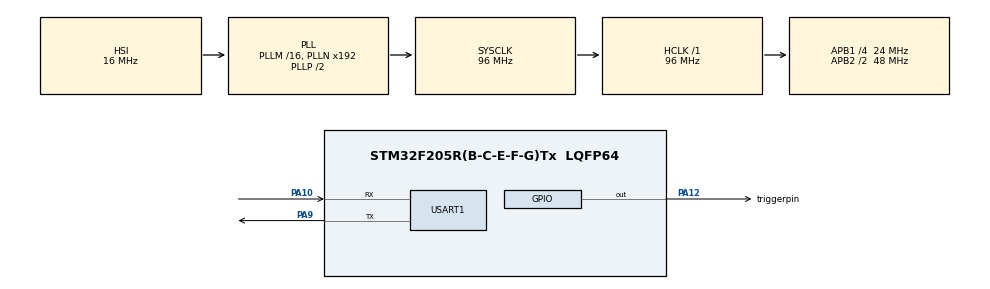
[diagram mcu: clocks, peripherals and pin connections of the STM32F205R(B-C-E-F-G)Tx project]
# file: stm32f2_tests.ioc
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Mcu.Family=STM32F2
Mcu.Name=STM32F205R(B-C-E-F-G)Tx
Mcu.Package=LQFP64
NVIC.PriorityGroup=NVIC_PRIORITYGROUP_4
PA10.Mode=Asynchronous
PA10.Signal=USART1_RX
PA12.GPIO_Label=triggerpin
PA12.GPIO_Speed=GPIO_SPEED_FREQ_VERY_HIGH
PA12.Signal=GPIO_Output
PA9.Mode=Asynchronous
PA9.Signal=USART1_TX
ProjectManager.HeapSize=0x200
ProjectManager.StackSize=0x400
ProjectManager.TargetToolchain=STM32CubeIDE
RCC.48MHZClocksFreq_Value=48000000
RCC.AHBFreq_Value=96000000
RCC.APB1CLKDivider=RCC_HCLK_DIV4
RCC.APB1Freq_Value=24000000
RCC.APB1TimFreq_Value=48000000
RCC.APB2CLKDivider=RCC_HCLK_DIV2
RCC.APB2Freq_Value=48000000
RCC.APB2TimFreq_Value=96000000
RCC.CortexFreq_Value=96000000
RCC.HCLKFreq_Value=96000000
RCC.HSE_VALUE=25000000
RCC.HSI_VALUE=16000000
RCC.LSE_VALUE=32768
RCC.SYSCLKFreq_VALUE=96000000
RCC.SYSCLKSource=RCC_SYSCLKSOURCE_PLLCLK
RCC.VCOOutputFreq_Value=192000000
USART1.Parity=PARITY_EVEN
USART1.VirtualMode=VM_ASYNC
board=custom

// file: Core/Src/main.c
/* USER CODE BEGIN Header */
/**
 ******************************************************************************
 * @file           : main.c
 * @brief          : Main program body
 ******************************************************************************
 * @attention
 *
 * Copyright (c) 2023 STMicroelectronics.
 * All rights reserved.
 *
 * This software is licensed under terms that can be found in the LICENSE file
 * in the root directory of this software component.
 * If no LICENSE file comes with this software, it is provided AS-IS.
 *
 ******************************************************************************
 */
/* USER CODE END Header */
#include "main.h"

/* USER CODE BEGIN Includes */
#include <stdio.h>
#include <string.h>
#include <stdlib.h>
/* USER CODE END Includes */

UART_HandleTypeDef huart1;

void SystemClock_Config(void);
static void MX_GPIO_Init(void);
static void MX_USART1_UART_Init(void);
/* USER CODE BEGIN PFP */

#ifdef __GNUC__
#define PUTCHAR_PROTOTYPE int __io_putchar(int ch)
#else
#define PUTCHAR_PROTOTYPE int fputc(int ch, FILE *f)
#endif

PUTCHAR_PROTOTYPE
{
	HAL_UART_Transmit(&huart1, (uint8_t *)&ch, 1, HAL_MAX_DELAY);
	return ch;
}

/* USER CODE END PFP */

/* USER CODE BEGIN 0 */

void print_hex_memory(void *mem, uint32_t len) {
	uint32_t i;
	unsigned char *p = (unsigned char *)mem;

	for (i=0;i<len;i++) {
		printf("0x%02x ", p[i]);
	}
	printf("\n");
}

// Lennert: Taken from a ChipWhisperer example
void glitch(void)
{
	unsigned int k = 0;
	//Declared volatile to avoid optimizing away loop.
	//This also adds lots of SRAM access
	volatile uint16_t i, j;
	volatile unsigned int cnt;
	cnt = 0;

	HAL_GPIO_WritePin(triggerpin_GPIO_Port, triggerpin_Pin, GPIO_PIN_SET);
	for(i=0; i<50; i++){
		for(j=0; j<50; j++){
			cnt++;
		}
	}
	HAL_GPIO_WritePin(triggerpin_GPIO_Port, triggerpin_Pin, GPIO_PIN_RESET);

	printf("%u %u %u %u\n", cnt, i, j, k++);
}

/* USER CODE END 0 */

int main(void)
{

  /* MCU Configuration--------------------------------------------------------*/

  /* Reset of all peripherals, Initializes the Flash interface and the Systick. */
  HAL_Init();

  /* Configure the system clock */
  SystemClock_Config();

  /* Initialize all configured peripherals */
  /* USER CODE BEGIN 2 */
  MX_GPIO_Init();
  HAL_GPIO_WritePin(triggerpin_GPIO_Port, triggerpin_Pin, GPIO_PIN_SET);
  MX_USART1_UART_Init();
  printf("Hello!\n");
  HAL_GPIO_WritePin(triggerpin_GPIO_Port, triggerpin_Pin, GPIO_PIN_RESET);
  /* USER CODE END 2 */
  uint8_t *mempointer;
  uint32_t address;
  char *str;
  uint8_t buf[10];
  char cmd;

  static const char secret[] = "SECRET_STRING.\n";

  /* USER CODE BEGIN 3 */
  while (1)
  {
	  HAL_UART_Receive (&huart1, buf, 1, 100);
	  cmd = (char)buf[0];

	  switch(cmd) {
	  case 'A':
		  HAL_GPIO_WritePin(triggerpin_GPIO_Port, triggerpin_Pin, GPIO_PIN_SET);
		  str = (char *) malloc(255);
		  strcpy(str, "AAAAAAAAAAAAAAAAAAAAAAAAAAAAAAAAAAAAAAAAAAAAAAAAAAAAAAAAAAAAAAAAAAAAAAAAAAAAAAAAAAAAAAAAAAAAAAAAAAAAAAAAAAAAAAAAAAAAAAAAAAAAAAAAAAAAAAAAAAAAAAAAAAAAAAAAAAAAAAAAAAAAAAAAAAAAAAAAAAAAAAAAAAAAAAAAAAAAAAAAAAAAAAAAAAAAAAAAAAAAAAAAAAAAAAAAAAAAAAAAAAAAAAAAAAAAAA");
		  printf("Address = %p\n", str);
		  HAL_GPIO_WritePin(triggerpin_GPIO_Port, triggerpin_Pin, GPIO_PIN_RESET);
		  break;

	  case 'B':
		  HAL_GPIO_WritePin(triggerpin_GPIO_Port, triggerpin_Pin, GPIO_PIN_SET);
		  HAL_UART_Receive (&huart1, buf, 4, 10000);
		  address = (buf[0] << 24) | (buf[1] << 16) | (buf[2] << 8) | buf[3];
		  mempointer = (uint8_t *)address;
		  HAL_UART_Transmit(&huart1, mempointer, 256, 250);
		  fflush(stdout);
		  HAL_GPIO_WritePin(triggerpin_GPIO_Port, triggerpin_Pin, GPIO_PIN_RESET);
		  break;

	  case 'C':
		  HAL_GPIO_WritePin(triggerpin_GPIO_Port, triggerpin_Pin, GPIO_PIN_SET);
		  printf(secret);
		  HAL_GPIO_WritePin(triggerpin_GPIO_Port, triggerpin_Pin, GPIO_PIN_RESET);
		  break;

	  case 'D':
		  glitch();
		  break;

	  case 'E':
		  // https://stackoverflow.com/questions/8158007/how-to-jump-the-program-execution-to-a-specific-address-in-c
		  // void *ptr = (void *)0x1234567;  // a random memory address
		  //goto *ptr;                      // jump there -- probably crash

		  HAL_UART_Receive (&huart1, buf, 4, 10000);
		  address = (buf[0] << 24) | (buf[1] << 16) | (buf[2] << 8) | buf[3];
		  void (*foo)(void) = (void (*)())address;

		  HAL_GPIO_WritePin(triggerpin_GPIO_Port, triggerpin_Pin, GPIO_PIN_SET);
		  foo();
		  //printf(secret);
		  HAL_GPIO_WritePin(triggerpin_GPIO_Port, triggerpin_Pin, GPIO_PIN_RESET);
		  break;

	  default:
		  break;
	  }

	  buf[0] = 0;
  }
  /* USER CODE END 3 */
}

void SystemClock_Config(void)
{
  RCC_OscInitTypeDef RCC_OscInitStruct = {0};
  RCC_ClkInitTypeDef RCC_ClkInitStruct = {0};

  /** Initializes the RCC Oscillators according to the specified parameters
  * in the RCC_OscInitTypeDef structure.
  */
  RCC_OscInitStruct.OscillatorType = RCC_OSCILLATORTYPE_HSI;
  RCC_OscInitStruct.HSIState = RCC_HSI_ON;
  RCC_OscInitStruct.HSICalibrationValue = RCC_HSICALIBRATION_DEFAULT;
  RCC_OscInitStruct.PLL.PLLState = RCC_PLL_ON;
  RCC_OscInitStruct.PLL.PLLSource = RCC_PLLSOURCE_HSI;
  RCC_OscInitStruct.PLL.PLLM = 16;
  RCC_OscInitStruct.PLL.PLLN = 192;
  RCC_OscInitStruct.PLL.PLLP = RCC_PLLP_DIV2;
  RCC_OscInitStruct.PLL.PLLQ = 4;
  if (HAL_RCC_OscConfig(&RCC_OscInitStruct) != HAL_OK)
  {
    Error_Handler();
  }

  /** Initializes the CPU, AHB and APB buses clocks
  */
  RCC_ClkInitStruct.ClockType = RCC_CLOCKTYPE_HCLK|RCC_CLOCKTYPE_SYSCLK
                              |RCC_CLOCKTYPE_PCLK1|RCC_CLOCKTYPE_PCLK2;
  RCC_ClkInitStruct.SYSCLKSource = RCC_SYSCLKSOURCE_PLLCLK;
  RCC_ClkInitStruct.AHBCLKDivider = RCC_SYSCLK_DIV1;
  RCC_ClkInitStruct.APB1CLKDivider = RCC_HCLK_DIV4;
  RCC_ClkInitStruct.APB2CLKDivider = RCC_HCLK_DIV2;

  if (HAL_RCC_ClockConfig(&RCC_ClkInitStruct, FLASH_LATENCY_3) != HAL_OK)
  {
    Error_Handler();
  }
}

static void MX_USART1_UART_Init(void)
{

  huart1.Instance = USART1;
  huart1.Init.BaudRate = 115200;
  huart1.Init.WordLength = UART_WORDLENGTH_9B;
  huart1.Init.StopBits = UART_STOPBITS_1;
  huart1.Init.Parity = UART_PARITY_EVEN;
  huart1.Init.Mode = UART_MODE_TX_RX;
  huart1.Init.HwFlowCtl = UART_HWCONTROL_NONE;
  huart1.Init.OverSampling = UART_OVERSAMPLING_16;
  if (HAL_UART_Init(&huart1) != HAL_OK)
  {
    Error_Handler();
  }

}

static void MX_GPIO_Init(void)
{
  GPIO_InitTypeDef GPIO_InitStruct = {0};

  /* GPIO Ports Clock Enable */
  __HAL_RCC_GPIOA_CLK_ENABLE();

  /*Configure GPIO pin Output Level */
  HAL_GPIO_WritePin(triggerpin_GPIO_Port, triggerpin_Pin, GPIO_PIN_RESET);

  /*Configure GPIO pin : triggerpin_Pin */
  GPIO_InitStruct.Pin = triggerpin_Pin;
  GPIO_InitStruct.Mode = GPIO_MODE_OUTPUT_PP;
  GPIO_InitStruct.Pull = GPIO_NOPULL;
  GPIO_InitStruct.Speed = GPIO_SPEED_FREQ_VERY_HIGH;
  HAL_GPIO_Init(triggerpin_GPIO_Port, &GPIO_InitStruct);

}

void Error_Handler(void)
{
	__disable_irq();
	while (1)
	{
	}
}
